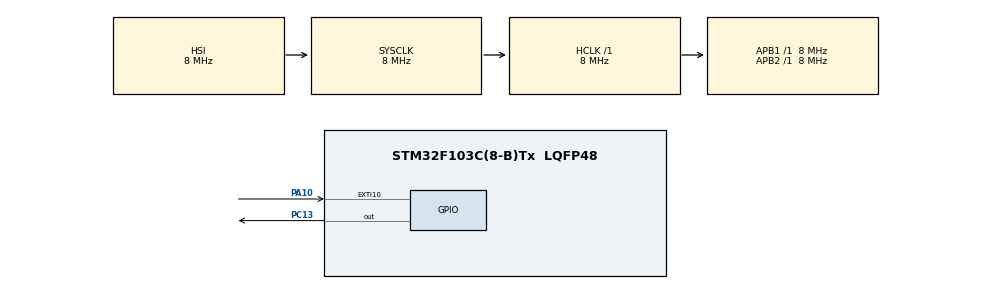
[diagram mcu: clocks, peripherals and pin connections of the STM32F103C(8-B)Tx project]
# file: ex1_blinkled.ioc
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Mcu.Family=STM32F1
Mcu.Name=STM32F103C(8-B)Tx
Mcu.Package=LQFP48
NVIC.EXTI15_10_IRQn=true\:15\:0\:true\:false\:true\:true\:true\:true
NVIC.PriorityGroup=NVIC_PRIORITYGROUP_4
NVIC.TIM1_UP_IRQn=true\:0\:0\:false\:false\:true\:true\:true\:true
PA10.GPIO_ModeDefaultEXTI=GPIO_MODE_IT_FALLING
PA10.GPIO_PuPd=GPIO_PULLUP
PA10.Signal=GPXTI10
PA13.Mode=Serial_Wire
PA13.Signal=SYS_JTMS-SWDIO
PA14.Mode=Serial_Wire
PA14.Signal=SYS_JTCK-SWCLK
PC13-TAMPER-RTC.GPIO_ModeDefaultOutputPP=GPIO_MODE_OUTPUT_OD
PC13-TAMPER-RTC.GPIO_PuPd=GPIO_NOPULL
PC13-TAMPER-RTC.PinState=GPIO_PIN_SET
PC13-TAMPER-RTC.Signal=GPIO_Output
PD0-OSC_IN.Mode=HSE-External-Oscillator
PD0-OSC_IN.Signal=RCC_OSC_IN
PD1-OSC_OUT.Mode=HSE-External-Oscillator
PD1-OSC_OUT.Signal=RCC_OSC_OUT
ProjectManager.HeapSize=0x200
ProjectManager.StackSize=0x400
ProjectManager.TargetToolchain=MDK-ARM V5.32
RCC.AHBFreq_Value=8000000
RCC.APB1Freq_Value=8000000
RCC.APB1TimFreq_Value=8000000
RCC.APB2Freq_Value=8000000
RCC.APB2TimFreq_Value=8000000
RCC.HCLKFreq_Value=8000000
RCC.PLLSourceVirtual=RCC_PLLSOURCE_HSE
RCC.SYSCLKFreq_VALUE=8000000
RCC.USBFreq_Value=16000000
TIM1.AutoReloadPreload=TIM_AUTORELOAD_PRELOAD_ENABLE
TIM1.Period=999
TIM1.Prescaler=7
VP_TIM1_VS_ClockSourceINT.Mode=Internal
board=custom

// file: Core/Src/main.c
/* USER CODE BEGIN Header */
/**
  ******************************************************************************
  * @file           : main.c
  * @brief          : Main program body
  ******************************************************************************
  * @attention
  *
  * Copyright (c) 2026 STMicroelectronics.
  * All rights reserved.
  *
  * This software is licensed under terms that can be found in the LICENSE file
  * in the root directory of this software component.
  * If no LICENSE file comes with this software, it is provided AS-IS.
  *
  ******************************************************************************
  */
/* USER CODE END Header */
#include "main.h"
#include "tim.h"
#include "gpio.h"

/* USER CODE BEGIN PV */
static volatile uint32_t currenttime = 0 ;
volatile uint8_t flag = 0 ;

volatile uint8_t flag_a0 = 0 ;
volatile uint8_t flag_a = 0 ;
volatile uint8_t flag_b = 0 ;

/* USER CODE END PV */

void SystemClock_Config(void);

/* USER CODE BEGIN 0 */
void HAL_TIM_PeriodElapsedCallback(TIM_HandleTypeDef *htim)
{
		if(htim == &htim1)
		{
			currenttime++ ;

		}

}

static uint32_t get_tick(void)
{

		return currenttime ;

}

/* USER CODE END 0 */

int main(void)
{

  /* MCU Configuration--------------------------------------------------------*/

  /* Reset of all peripherals, Initializes the Flash interface and the Systick. */
  HAL_Init();

  /* Configure the system clock */
  SystemClock_Config();

  /* Initialize all configured peripherals */
  MX_GPIO_Init();
  MX_TIM1_Init();
  /* USER CODE BEGIN 2 */
	HAL_TIM_Base_Start_IT(&htim1) ;
  /* USER CODE END 2 */

  /* Infinite loop */
  /* USER CODE BEGIN WHILE */
  while (1)
  {
    uint32_t pressdu = 0 ;
		uint32_t presstime = 0;

		if (flag == 1)
		{
			HAL_Delay(20) ;
			if (HAL_GPIO_ReadPin(GPIOA , GPIO_PIN_10) == GPIO_PIN_RESET)
			{

				presstime = get_tick();

				while(HAL_GPIO_ReadPin(GPIOA , GPIO_PIN_10) == GPIO_PIN_RESET)
				{}
				HAL_Delay(20) ;

				if (HAL_GPIO_ReadPin(GPIOA , GPIO_PIN_10) == GPIO_PIN_SET)
				{

					pressdu = get_tick() - presstime ;

					flag = 0 ;
				}

				if ( pressdu <= 1000 && pressdu > 20)
				{
					flag_a0 = 1 ;

				}
				else if( pressdu >= 1000 )
				{

					flag_a0 = 0 ;
				}

				if (flag_a0 == 1)
				{

					if (flag_a == 0)
					{
						HAL_GPIO_WritePin(GPIOC , GPIO_PIN_13 , GPIO_PIN_RESET) ;
						flag_a = 1 ;
					}
					else
					{

						HAL_GPIO_WritePin(GPIOC , GPIO_PIN_13 , GPIO_PIN_SET) ;
						flag_a = 0 ;
					}

				}

				if (flag_a0 == 0)
				{
					if (flag_b == 0)
					{
						flag_b = 1 ;
						while(HAL_GPIO_ReadPin(GPIOA , GPIO_PIN_10) == GPIO_PIN_SET)
						{
							HAL_GPIO_TogglePin(GPIOC , GPIO_PIN_13) ;
							HAL_Delay(100) ;
						}

					}
					else
					{

						flag_b = 0 ;

						if (flag_a == 1)
						{
							HAL_GPIO_WritePin(GPIOC , GPIO_PIN_13 , GPIO_PIN_RESET) ;
							flag_a = 1 ;
						}
						else
						{

							HAL_GPIO_WritePin(GPIOC , GPIO_PIN_13 , GPIO_PIN_SET) ;
							flag_a = 0 ;
						}

					}

				}

			}

		}

    /* USER CODE END WHILE */

  }
}

void SystemClock_Config(void)
{
  RCC_OscInitTypeDef RCC_OscInitStruct = {0};
  RCC_ClkInitTypeDef RCC_ClkInitStruct = {0};

  /** Initializes the RCC Oscillators according to the specified parameters
  * in the RCC_OscInitTypeDef structure.
  */
  RCC_OscInitStruct.OscillatorType = RCC_OSCILLATORTYPE_HSI;
  RCC_OscInitStruct.HSIState = RCC_HSI_ON;
  RCC_OscInitStruct.HSICalibrationValue = RCC_HSICALIBRATION_DEFAULT;
  RCC_OscInitStruct.PLL.PLLState = RCC_PLL_NONE;
  if (HAL_RCC_OscConfig(&RCC_OscInitStruct) != HAL_OK)
  {
    Error_Handler();
  }

  /** Initializes the CPU, AHB and APB buses clocks
  */
  RCC_ClkInitStruct.ClockType = RCC_CLOCKTYPE_HCLK|RCC_CLOCKTYPE_SYSCLK
                              |RCC_CLOCKTYPE_PCLK1|RCC_CLOCKTYPE_PCLK2;
  RCC_ClkInitStruct.SYSCLKSource = RCC_SYSCLKSOURCE_HSI;
  RCC_ClkInitStruct.AHBCLKDivider = RCC_SYSCLK_DIV1;
  RCC_ClkInitStruct.APB1CLKDivider = RCC_HCLK_DIV1;
  RCC_ClkInitStruct.APB2CLKDivider = RCC_HCLK_DIV1;

  if (HAL_RCC_ClockConfig(&RCC_ClkInitStruct, FLASH_LATENCY_0) != HAL_OK)
  {
    Error_Handler();
  }
}

/* USER CODE BEGIN 4 */
void HAL_GPIO_EXTI_Callback(uint16_t GPIO_Pin)
{
	if (GPIO_Pin == GPIO_PIN_10)
	{

		flag = 1 ;

	}

}
/* USER CODE END 4 */

void Error_Handler(void)
{
  __disable_irq();
  while (1)
  {
  }
}
